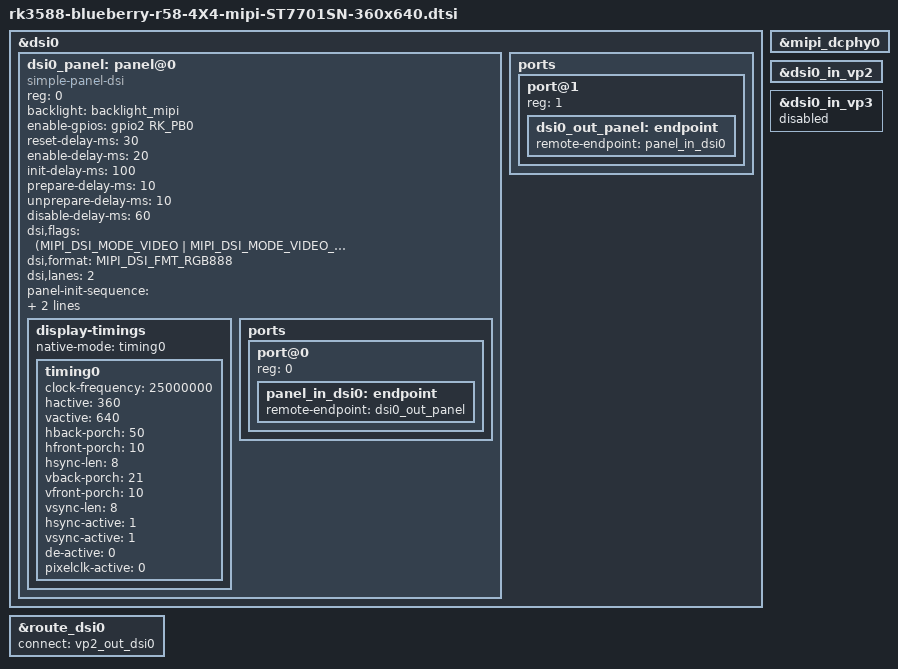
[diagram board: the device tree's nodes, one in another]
// SPDX-License-Identifier: (GPL-2.0+ OR MIT)
/*
 * Copyright (c) 2021 Rockchip Electronics Co., Ltd.
 *
 */

#include "dt-bindings/usb/pd.h"



&dsi0 {
	status = "okay";
	//rockchip,lane-rate = <1000>;
	dsi0_panel: panel@0 {
		status = "okay";
		compatible = "simple-panel-dsi";
		reg = <0>;
		backlight = <&backlight_mipi>;
		//power-supply = <&vcc3v3_mipi_lcd_power>;
		//reset-gpios =  <&gpio3 RK_PC4 GPIO_ACTIVE_LOW>; 
		enable-gpios = <&gpio2 RK_PB0 GPIO_ACTIVE_HIGH>;
		reset-delay-ms = <30>;
		enable-delay-ms = <20>;
		init-delay-ms = <100>;
		prepare-delay-ms = <10>;
		unprepare-delay-ms = <10>;
		disable-delay-ms = <60>;
		dsi,flags = <(MIPI_DSI_MODE_VIDEO | MIPI_DSI_MODE_VIDEO_BURST |
			MIPI_DSI_MODE_LPM | MIPI_DSI_MODE_EOT_PACKET)>;
		dsi,format = <MIPI_DSI_FMT_RGB888>;
		dsi,lanes  = <2>;

		panel-init-sequence = [
			//29 00 04 FF 98 81 03

			//GIP_1

			//23 00 02 01 00
			05 78 01 11
			//23 00 02 B3 80
			//Delay 120
			29 00 06 FF 77 01 00 00 10
			29 00 03 C0 3B 00
			29 00 03 C1 0B 02
			29 00 03 C2 00 02
			23 00 02 CC 10
			23 00 02 CD 00
			29 00 11 B0 02 13 1B 0D 10 05 08 07 07 24 04 11 0E 2C 33 1D
			29 00 11 B1 05 13 1B 0D 11 05 08 07 07 24 04 11 0E 2C 33 1D
			29 00 06 FF 77 01 00 00 11
			23 00 02 B0 5D
			23 00 02 B1 43
			23 00 02 B2 81
			23 00 02 B3 80
			23 00 02 B5 43
			23 00 02 B7 85
			23 00 02 B8 20
			23 00 02 C1 78
			23 00 02 C2 78
			23 00 02 D0 88
			29 00 04 E0 00 00 02
			29 00 0C E1 03 A0 00 00 04 A0 00 00 00 20 20
			29 00 0E E2 00 00 00 00 00 00 00 00 00 00 00 00 00
			29 00 05 E3 00 00 11 00
			29 00 03 E4 22 00
			29 00 11 E5 05 EC A0 A0 07 EE A0 A0 00 00 00 00 00 00 00 00
			29 00 05 E6 00 00 11 00
			29 00 03 E7 22 00
			29 00 11 E8 06 ED A0 A0 00 EF A0 A0 00 00 00 00 00 00 00 00
			29 00 08 EB 00 00 40 40 00 00 00
			29 00 11 ED FF FF FF BA 0A BF 45 FF FF 54 FB A0 AB FF FF FF
			29 00 07 EF 10 0D 04 08 3F 1F
			29 00 06 FF 77 01 00 00 13
			23 00 02 EF 08
			29 00 06 FF 77 01 00 00 00
			05 78 01 11   

			05 14 01 29 
			//Delay 20
			23 00 02 36 00
			23 00 02 3A 60
		];

		panel-exit-sequence = [
		];

		display-timings {
			native-mode = <&timing0>;
			/*timing0: timing0 {
				clock-frequency = <25000000>;  //159391260  159747840
				hactive = <480>;
				vactive = <640>; 
				hback-porch = <20>;
				hfront-porch = <10>;
				hsync-len = <4>;
				vback-porch = <14>;
				vfront-porch = <8>;
				vsync-len = <4>;
				hsync-active = <1>;
				vsync-active = <1>;
				de-active = <0>;
				pixelclk-active = <0>;
				};*/

				timing0: timing0 {
				clock-frequency = <25000000>;  //159391260  159747840
				hactive = <360>;
				vactive = <640>; 
				hback-porch = <50>;
				hfront-porch = <10>;
				hsync-len = <8>;
				vback-porch = <21>;
				vfront-porch = <10>;
				vsync-len = <8>;
				hsync-active = <1>;
				vsync-active = <1>;
				de-active = <0>;
				pixelclk-active = <0>;
				};
				
			/*timing0: timing0 {
				clock-frequency = <35000000>;  //159391260  159747840
				hactive = <360>;
				vactive = <640>; 
				hback-porch = <50>;
				hfront-porch = <10>;
				hsync-len = <8>;
				vback-porch = <11>;
				vfront-porch = <2>;
				vsync-len = <8>;
				hsync-active = <1>;
				vsync-active = <1>;
				de-active = <0>;
				pixelclk-active = <0>;
				};*/
		};

		ports {
			#address-cells = <1>;
			#size-cells = <0>;

			port@0 {
				reg = <0>;
				panel_in_dsi0: endpoint {
					remote-endpoint = <&dsi0_out_panel>;
				};
			};
		};
	};

		ports {
			#address-cells = <1>;
			#size-cells = <0>;

			port@1 {
				reg = <1>;
				dsi0_out_panel: endpoint {
					remote-endpoint = <&panel_in_dsi0>;
				};
			};
		};
	
};

&dsi0 {
	status = "okay";
};

&mipi_dcphy0 {
	status = "okay";
};

&dsi0_in_vp2 {
	status = "okay";
};

&dsi0_in_vp3 {
	status = "disabled";
};

&route_dsi0 {
	status = "okay";
	connect = <&vp2_out_dsi0>;
};
